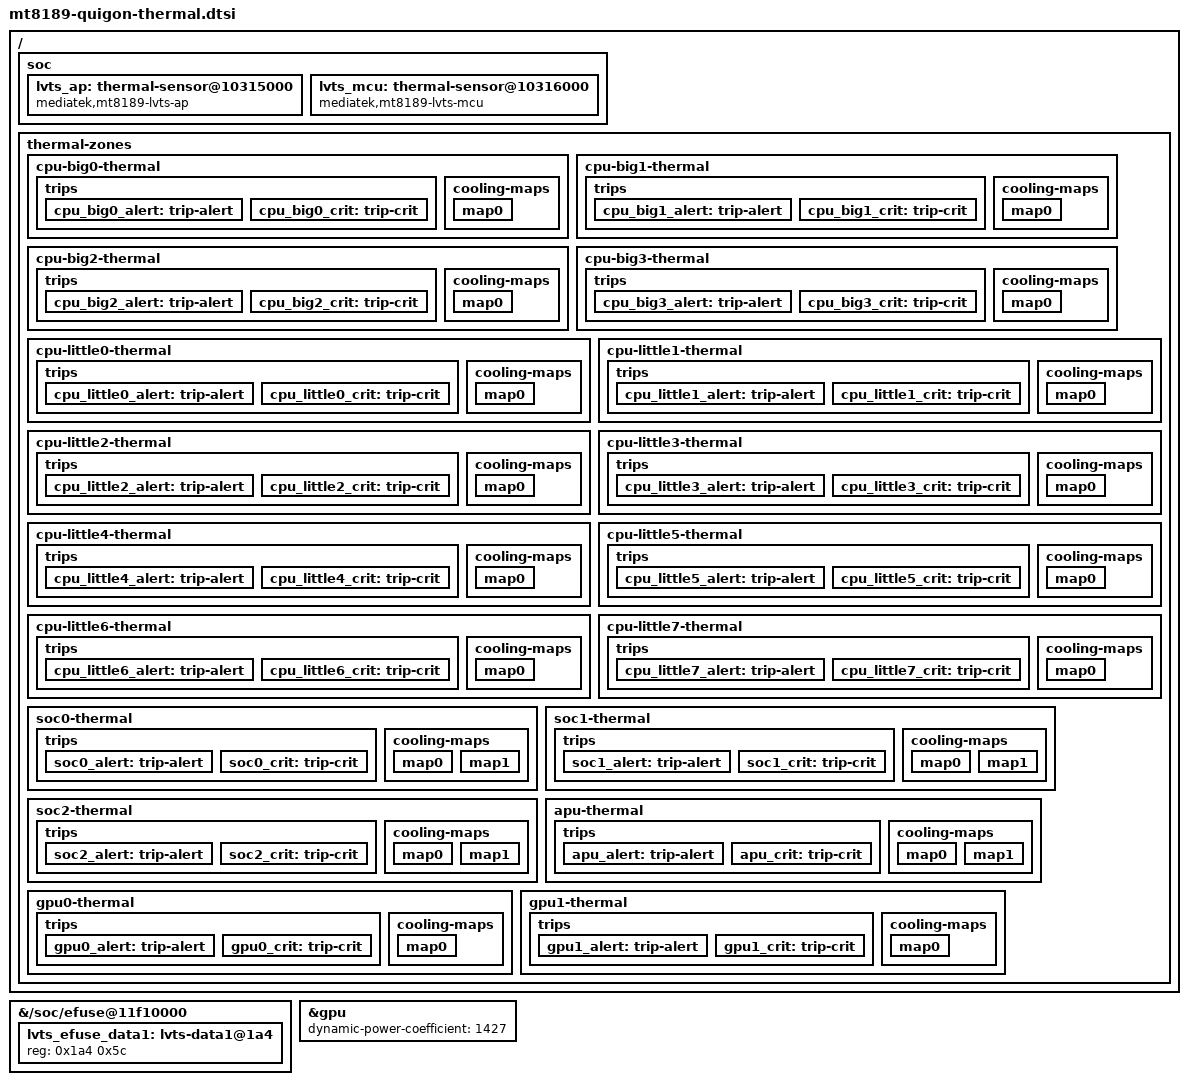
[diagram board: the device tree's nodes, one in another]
// SPDX-License-Identifier: (GPL-2.0 OR MIT)
/*
 * quigon thermal: the MT8189 LVTS sensors (two domains, 18 sensors) with thermal zones that throttle the CPU clusters
 * (mediatek-cpufreq-hw cooling devices) and the GPU (Panfrost devfreq cooling). Needs the MT8189 LVTS driver patch
 * (compatibles "mediatek,mt8189-lvts-mcu"/"-ap" and the MT8189_* sensor ids in mediatek,lvts-thermal.h).
 *
 * The firmware (coreboot) sets up every LVTS controller (device init, RC calibration, sampling, and the 119 C
 * hardware reset through the thermal protection stage 3) and marks it with 0x555 in LVTS_SPARE0; the driver keeps
 * that setup and only reads the golden temperature from the efuse. Like ChromeOS, no LVTS clock or reset is
 * described (the clock gate isn't modelled and resetting would drop the firmware calibration and protection); the
 * binding wants a clock, so the always-on 26 MHz reference stands in.
 *
 * Sensor layout from ChromeOS's mt8189.dtsi and coreboot: MCU controller 0 = big CPUs (2 sensors per A78),
 * MCU controllers 1-2 = little CPUs, AP controller 0 = SoC top x3 + APU, AP controller 1 (MFG) = GPU x2.
 * Efuse words 0-22 at 0x1a4: golden temperature in word 0 [7:0], per-sensor calibration in [23:0].
 *
 * Policy: ChromeOS throttles on one "max of all sensors" zone (power allocator, target 85 C, critical 115 C) and
 * gives every sensor a 119 C critical trip. Mainline LVTS has no max-of-all sensor, so every sensor gets a passive
 * trip at 85 C (step_wise) mapped to the cooling devices next to it, and a critical trip at 115 C.
 */
#include <dt-bindings/thermal/thermal.h>
#include <dt-bindings/thermal/mediatek,lvts-thermal.h>

&{/soc/efuse@11f10000} {
	lvts_efuse_data1: lvts-data1@1a4 {
		reg = <0x1a4 0x5c>;
	};
};

&gpu {
	/* ChromeOS value; lets the devfreq cooling device register an energy model */
	dynamic-power-coefficient = <1427>;
};

/ {
	soc {
		lvts_ap: thermal-sensor@10315000 {
			compatible = "mediatek,mt8189-lvts-ap";
			reg = <0 0x10315000 0 0x1000>;
			interrupts = <GIC_SPI 218 IRQ_TYPE_LEVEL_HIGH 0>;
			clocks = <&clk26m>;
			nvmem-cells = <&lvts_efuse_data1>;
			nvmem-cell-names = "lvts-calib-data-1";
			#thermal-sensor-cells = <1>;
		};

		lvts_mcu: thermal-sensor@10316000 {
			compatible = "mediatek,mt8189-lvts-mcu";
			reg = <0 0x10316000 0 0x1000>;
			interrupts = <GIC_SPI 219 IRQ_TYPE_LEVEL_HIGH 0>;
			clocks = <&clk26m>;
			nvmem-cells = <&lvts_efuse_data1>;
			nvmem-cell-names = "lvts-calib-data-1";
			#thermal-sensor-cells = <1>;
		};
	};

	thermal-zones {
		cpu-big0-thermal {
			polling-delay = <1000>;
			polling-delay-passive = <100>;
			thermal-sensors = <&lvts_mcu MT8189_MCU_BIG_CPU0>;

			trips {
				cpu_big0_alert: trip-alert {
					temperature = <85000>;
					hysteresis = <2000>;
					type = "passive";
				};

				cpu_big0_crit: trip-crit {
					temperature = <115000>;
					hysteresis = <0>;
					type = "critical";
				};
			};

			cooling-maps {
				map0 {
					trip = <&cpu_big0_alert>;
					cooling-device = <&cpu6 THERMAL_NO_LIMIT THERMAL_NO_LIMIT>,
							 <&cpu7 THERMAL_NO_LIMIT THERMAL_NO_LIMIT>;
				};
			};
		};

		cpu-big1-thermal {
			polling-delay = <1000>;
			polling-delay-passive = <100>;
			thermal-sensors = <&lvts_mcu MT8189_MCU_BIG_CPU1>;

			trips {
				cpu_big1_alert: trip-alert {
					temperature = <85000>;
					hysteresis = <2000>;
					type = "passive";
				};

				cpu_big1_crit: trip-crit {
					temperature = <115000>;
					hysteresis = <0>;
					type = "critical";
				};
			};

			cooling-maps {
				map0 {
					trip = <&cpu_big1_alert>;
					cooling-device = <&cpu6 THERMAL_NO_LIMIT THERMAL_NO_LIMIT>,
							 <&cpu7 THERMAL_NO_LIMIT THERMAL_NO_LIMIT>;
				};
			};
		};

		cpu-big2-thermal {
			polling-delay = <1000>;
			polling-delay-passive = <100>;
			thermal-sensors = <&lvts_mcu MT8189_MCU_BIG_CPU2>;

			trips {
				cpu_big2_alert: trip-alert {
					temperature = <85000>;
					hysteresis = <2000>;
					type = "passive";
				};

				cpu_big2_crit: trip-crit {
					temperature = <115000>;
					hysteresis = <0>;
					type = "critical";
				};
			};

			cooling-maps {
				map0 {
					trip = <&cpu_big2_alert>;
					cooling-device = <&cpu6 THERMAL_NO_LIMIT THERMAL_NO_LIMIT>,
							 <&cpu7 THERMAL_NO_LIMIT THERMAL_NO_LIMIT>;
				};
			};
		};

		cpu-big3-thermal {
			polling-delay = <1000>;
			polling-delay-passive = <100>;
			thermal-sensors = <&lvts_mcu MT8189_MCU_BIG_CPU3>;

			trips {
				cpu_big3_alert: trip-alert {
					temperature = <85000>;
					hysteresis = <2000>;
					type = "passive";
				};

				cpu_big3_crit: trip-crit {
					temperature = <115000>;
					hysteresis = <0>;
					type = "critical";
				};
			};

			cooling-maps {
				map0 {
					trip = <&cpu_big3_alert>;
					cooling-device = <&cpu6 THERMAL_NO_LIMIT THERMAL_NO_LIMIT>,
							 <&cpu7 THERMAL_NO_LIMIT THERMAL_NO_LIMIT>;
				};
			};
		};

		cpu-little0-thermal {
			polling-delay = <1000>;
			polling-delay-passive = <100>;
			thermal-sensors = <&lvts_mcu MT8189_MCU_LITTLE_CPU0>;

			trips {
				cpu_little0_alert: trip-alert {
					temperature = <85000>;
					hysteresis = <2000>;
					type = "passive";
				};

				cpu_little0_crit: trip-crit {
					temperature = <115000>;
					hysteresis = <0>;
					type = "critical";
				};
			};

			cooling-maps {
				map0 {
					trip = <&cpu_little0_alert>;
					cooling-device = <&cpu0 THERMAL_NO_LIMIT THERMAL_NO_LIMIT>,
							 <&cpu1 THERMAL_NO_LIMIT THERMAL_NO_LIMIT>,
							 <&cpu2 THERMAL_NO_LIMIT THERMAL_NO_LIMIT>,
							 <&cpu3 THERMAL_NO_LIMIT THERMAL_NO_LIMIT>,
							 <&cpu4 THERMAL_NO_LIMIT THERMAL_NO_LIMIT>,
							 <&cpu5 THERMAL_NO_LIMIT THERMAL_NO_LIMIT>;
				};
			};
		};

		cpu-little1-thermal {
			polling-delay = <1000>;
			polling-delay-passive = <100>;
			thermal-sensors = <&lvts_mcu MT8189_MCU_LITTLE_CPU1>;

			trips {
				cpu_little1_alert: trip-alert {
					temperature = <85000>;
					hysteresis = <2000>;
					type = "passive";
				};

				cpu_little1_crit: trip-crit {
					temperature = <115000>;
					hysteresis = <0>;
					type = "critical";
				};
			};

			cooling-maps {
				map0 {
					trip = <&cpu_little1_alert>;
					cooling-device = <&cpu0 THERMAL_NO_LIMIT THERMAL_NO_LIMIT>,
							 <&cpu1 THERMAL_NO_LIMIT THERMAL_NO_LIMIT>,
							 <&cpu2 THERMAL_NO_LIMIT THERMAL_NO_LIMIT>,
							 <&cpu3 THERMAL_NO_LIMIT THERMAL_NO_LIMIT>,
							 <&cpu4 THERMAL_NO_LIMIT THERMAL_NO_LIMIT>,
							 <&cpu5 THERMAL_NO_LIMIT THERMAL_NO_LIMIT>;
				};
			};
		};

		cpu-little2-thermal {
			polling-delay = <1000>;
			polling-delay-passive = <100>;
			thermal-sensors = <&lvts_mcu MT8189_MCU_LITTLE_CPU2>;

			trips {
				cpu_little2_alert: trip-alert {
					temperature = <85000>;
					hysteresis = <2000>;
					type = "passive";
				};

				cpu_little2_crit: trip-crit {
					temperature = <115000>;
					hysteresis = <0>;
					type = "critical";
				};
			};

			cooling-maps {
				map0 {
					trip = <&cpu_little2_alert>;
					cooling-device = <&cpu0 THERMAL_NO_LIMIT THERMAL_NO_LIMIT>,
							 <&cpu1 THERMAL_NO_LIMIT THERMAL_NO_LIMIT>,
							 <&cpu2 THERMAL_NO_LIMIT THERMAL_NO_LIMIT>,
							 <&cpu3 THERMAL_NO_LIMIT THERMAL_NO_LIMIT>,
							 <&cpu4 THERMAL_NO_LIMIT THERMAL_NO_LIMIT>,
							 <&cpu5 THERMAL_NO_LIMIT THERMAL_NO_LIMIT>;
				};
			};
		};

		cpu-little3-thermal {
			polling-delay = <1000>;
			polling-delay-passive = <100>;
			thermal-sensors = <&lvts_mcu MT8189_MCU_LITTLE_CPU3>;

			trips {
				cpu_little3_alert: trip-alert {
					temperature = <85000>;
					hysteresis = <2000>;
					type = "passive";
				};

				cpu_little3_crit: trip-crit {
					temperature = <115000>;
					hysteresis = <0>;
					type = "critical";
				};
			};

			cooling-maps {
				map0 {
					trip = <&cpu_little3_alert>;
					cooling-device = <&cpu0 THERMAL_NO_LIMIT THERMAL_NO_LIMIT>,
							 <&cpu1 THERMAL_NO_LIMIT THERMAL_NO_LIMIT>,
							 <&cpu2 THERMAL_NO_LIMIT THERMAL_NO_LIMIT>,
							 <&cpu3 THERMAL_NO_LIMIT THERMAL_NO_LIMIT>,
							 <&cpu4 THERMAL_NO_LIMIT THERMAL_NO_LIMIT>,
							 <&cpu5 THERMAL_NO_LIMIT THERMAL_NO_LIMIT>;
				};
			};
		};

		cpu-little4-thermal {
			polling-delay = <1000>;
			polling-delay-passive = <100>;
			thermal-sensors = <&lvts_mcu MT8189_MCU_LITTLE_CPU4>;

			trips {
				cpu_little4_alert: trip-alert {
					temperature = <85000>;
					hysteresis = <2000>;
					type = "passive";
				};

				cpu_little4_crit: trip-crit {
					temperature = <115000>;
					hysteresis = <0>;
					type = "critical";
				};
			};

			cooling-maps {
				map0 {
					trip = <&cpu_little4_alert>;
					cooling-device = <&cpu0 THERMAL_NO_LIMIT THERMAL_NO_LIMIT>,
							 <&cpu1 THERMAL_NO_LIMIT THERMAL_NO_LIMIT>,
							 <&cpu2 THERMAL_NO_LIMIT THERMAL_NO_LIMIT>,
							 <&cpu3 THERMAL_NO_LIMIT THERMAL_NO_LIMIT>,
							 <&cpu4 THERMAL_NO_LIMIT THERMAL_NO_LIMIT>,
							 <&cpu5 THERMAL_NO_LIMIT THERMAL_NO_LIMIT>;
				};
			};
		};

		cpu-little5-thermal {
			polling-delay = <1000>;
			polling-delay-passive = <100>;
			thermal-sensors = <&lvts_mcu MT8189_MCU_LITTLE_CPU5>;

			trips {
				cpu_little5_alert: trip-alert {
					temperature = <85000>;
					hysteresis = <2000>;
					type = "passive";
				};

				cpu_little5_crit: trip-crit {
					temperature = <115000>;
					hysteresis = <0>;
					type = "critical";
				};
			};

			cooling-maps {
				map0 {
					trip = <&cpu_little5_alert>;
					cooling-device = <&cpu0 THERMAL_NO_LIMIT THERMAL_NO_LIMIT>,
							 <&cpu1 THERMAL_NO_LIMIT THERMAL_NO_LIMIT>,
							 <&cpu2 THERMAL_NO_LIMIT THERMAL_NO_LIMIT>,
							 <&cpu3 THERMAL_NO_LIMIT THERMAL_NO_LIMIT>,
							 <&cpu4 THERMAL_NO_LIMIT THERMAL_NO_LIMIT>,
							 <&cpu5 THERMAL_NO_LIMIT THERMAL_NO_LIMIT>;
				};
			};
		};

		cpu-little6-thermal {
			polling-delay = <1000>;
			polling-delay-passive = <100>;
			thermal-sensors = <&lvts_mcu MT8189_MCU_LITTLE_CPU6>;

			trips {
				cpu_little6_alert: trip-alert {
					temperature = <85000>;
					hysteresis = <2000>;
					type = "passive";
				};

				cpu_little6_crit: trip-crit {
					temperature = <115000>;
					hysteresis = <0>;
					type = "critical";
				};
			};

			cooling-maps {
				map0 {
					trip = <&cpu_little6_alert>;
					cooling-device = <&cpu0 THERMAL_NO_LIMIT THERMAL_NO_LIMIT>,
							 <&cpu1 THERMAL_NO_LIMIT THERMAL_NO_LIMIT>,
							 <&cpu2 THERMAL_NO_LIMIT THERMAL_NO_LIMIT>,
							 <&cpu3 THERMAL_NO_LIMIT THERMAL_NO_LIMIT>,
							 <&cpu4 THERMAL_NO_LIMIT THERMAL_NO_LIMIT>,
							 <&cpu5 THERMAL_NO_LIMIT THERMAL_NO_LIMIT>;
				};
			};
		};

		cpu-little7-thermal {
			polling-delay = <1000>;
			polling-delay-passive = <100>;
			thermal-sensors = <&lvts_mcu MT8189_MCU_LITTLE_CPU7>;

			trips {
				cpu_little7_alert: trip-alert {
					temperature = <85000>;
					hysteresis = <2000>;
					type = "passive";
				};

				cpu_little7_crit: trip-crit {
					temperature = <115000>;
					hysteresis = <0>;
					type = "critical";
				};
			};

			cooling-maps {
				map0 {
					trip = <&cpu_little7_alert>;
					cooling-device = <&cpu0 THERMAL_NO_LIMIT THERMAL_NO_LIMIT>,
							 <&cpu1 THERMAL_NO_LIMIT THERMAL_NO_LIMIT>,
							 <&cpu2 THERMAL_NO_LIMIT THERMAL_NO_LIMIT>,
							 <&cpu3 THERMAL_NO_LIMIT THERMAL_NO_LIMIT>,
							 <&cpu4 THERMAL_NO_LIMIT THERMAL_NO_LIMIT>,
							 <&cpu5 THERMAL_NO_LIMIT THERMAL_NO_LIMIT>;
				};
			};
		};

		soc0-thermal {
			polling-delay = <1000>;
			polling-delay-passive = <250>;
			thermal-sensors = <&lvts_ap MT8189_AP_SOC0>;

			trips {
				soc0_alert: trip-alert {
					temperature = <85000>;
					hysteresis = <2000>;
					type = "passive";
				};

				soc0_crit: trip-crit {
					temperature = <115000>;
					hysteresis = <0>;
					type = "critical";
				};
			};

			cooling-maps {
				map0 {
					trip = <&soc0_alert>;
					cooling-device = <&cpu0 THERMAL_NO_LIMIT THERMAL_NO_LIMIT>,
							 <&cpu1 THERMAL_NO_LIMIT THERMAL_NO_LIMIT>,
							 <&cpu2 THERMAL_NO_LIMIT THERMAL_NO_LIMIT>,
							 <&cpu3 THERMAL_NO_LIMIT THERMAL_NO_LIMIT>,
							 <&cpu4 THERMAL_NO_LIMIT THERMAL_NO_LIMIT>,
							 <&cpu5 THERMAL_NO_LIMIT THERMAL_NO_LIMIT>,
							 <&cpu6 THERMAL_NO_LIMIT THERMAL_NO_LIMIT>,
							 <&cpu7 THERMAL_NO_LIMIT THERMAL_NO_LIMIT>;
				};

				map1 {
					trip = <&soc0_alert>;
					cooling-device = <&gpu THERMAL_NO_LIMIT THERMAL_NO_LIMIT>;
				};
			};
		};

		soc1-thermal {
			polling-delay = <1000>;
			polling-delay-passive = <250>;
			thermal-sensors = <&lvts_ap MT8189_AP_SOC1>;

			trips {
				soc1_alert: trip-alert {
					temperature = <85000>;
					hysteresis = <2000>;
					type = "passive";
				};

				soc1_crit: trip-crit {
					temperature = <115000>;
					hysteresis = <0>;
					type = "critical";
				};
			};

			cooling-maps {
				map0 {
					trip = <&soc1_alert>;
					cooling-device = <&cpu0 THERMAL_NO_LIMIT THERMAL_NO_LIMIT>,
							 <&cpu1 THERMAL_NO_LIMIT THERMAL_NO_LIMIT>,
							 <&cpu2 THERMAL_NO_LIMIT THERMAL_NO_LIMIT>,
							 <&cpu3 THERMAL_NO_LIMIT THERMAL_NO_LIMIT>,
							 <&cpu4 THERMAL_NO_LIMIT THERMAL_NO_LIMIT>,
							 <&cpu5 THERMAL_NO_LIMIT THERMAL_NO_LIMIT>,
							 <&cpu6 THERMAL_NO_LIMIT THERMAL_NO_LIMIT>,
							 <&cpu7 THERMAL_NO_LIMIT THERMAL_NO_LIMIT>;
				};

				map1 {
					trip = <&soc1_alert>;
					cooling-device = <&gpu THERMAL_NO_LIMIT THERMAL_NO_LIMIT>;
				};
			};
		};

		soc2-thermal {
			polling-delay = <1000>;
			polling-delay-passive = <250>;
			thermal-sensors = <&lvts_ap MT8189_AP_SOC2>;

			trips {
				soc2_alert: trip-alert {
					temperature = <85000>;
					hysteresis = <2000>;
					type = "passive";
				};

				soc2_crit: trip-crit {
					temperature = <115000>;
					hysteresis = <0>;
					type = "critical";
				};
			};

			cooling-maps {
				map0 {
					trip = <&soc2_alert>;
					cooling-device = <&cpu0 THERMAL_NO_LIMIT THERMAL_NO_LIMIT>,
							 <&cpu1 THERMAL_NO_LIMIT THERMAL_NO_LIMIT>,
							 <&cpu2 THERMAL_NO_LIMIT THERMAL_NO_LIMIT>,
							 <&cpu3 THERMAL_NO_LIMIT THERMAL_NO_LIMIT>,
							 <&cpu4 THERMAL_NO_LIMIT THERMAL_NO_LIMIT>,
							 <&cpu5 THERMAL_NO_LIMIT THERMAL_NO_LIMIT>,
							 <&cpu6 THERMAL_NO_LIMIT THERMAL_NO_LIMIT>,
							 <&cpu7 THERMAL_NO_LIMIT THERMAL_NO_LIMIT>;
				};

				map1 {
					trip = <&soc2_alert>;
					cooling-device = <&gpu THERMAL_NO_LIMIT THERMAL_NO_LIMIT>;
				};
			};
		};

		apu-thermal {
			polling-delay = <1000>;
			polling-delay-passive = <250>;
			thermal-sensors = <&lvts_ap MT8189_AP_APU>;

			trips {
				apu_alert: trip-alert {
					temperature = <85000>;
					hysteresis = <2000>;
					type = "passive";
				};

				apu_crit: trip-crit {
					temperature = <115000>;
					hysteresis = <0>;
					type = "critical";
				};
			};

			cooling-maps {
				map0 {
					trip = <&apu_alert>;
					cooling-device = <&cpu0 THERMAL_NO_LIMIT THERMAL_NO_LIMIT>,
							 <&cpu1 THERMAL_NO_LIMIT THERMAL_NO_LIMIT>,
							 <&cpu2 THERMAL_NO_LIMIT THERMAL_NO_LIMIT>,
							 <&cpu3 THERMAL_NO_LIMIT THERMAL_NO_LIMIT>,
							 <&cpu4 THERMAL_NO_LIMIT THERMAL_NO_LIMIT>,
							 <&cpu5 THERMAL_NO_LIMIT THERMAL_NO_LIMIT>,
							 <&cpu6 THERMAL_NO_LIMIT THERMAL_NO_LIMIT>,
							 <&cpu7 THERMAL_NO_LIMIT THERMAL_NO_LIMIT>;
				};

				map1 {
					trip = <&apu_alert>;
					cooling-device = <&gpu THERMAL_NO_LIMIT THERMAL_NO_LIMIT>;
				};
			};
		};

		gpu0-thermal {
			polling-delay = <1000>;
			polling-delay-passive = <100>;
			thermal-sensors = <&lvts_ap MT8189_AP_GPU0>;

			trips {
				gpu0_alert: trip-alert {
					temperature = <85000>;
					hysteresis = <2000>;
					type = "passive";
				};

				gpu0_crit: trip-crit {
					temperature = <115000>;
					hysteresis = <0>;
					type = "critical";
				};
			};

			cooling-maps {
				map0 {
					trip = <&gpu0_alert>;
					cooling-device = <&gpu THERMAL_NO_LIMIT THERMAL_NO_LIMIT>;
				};
			};
		};

		gpu1-thermal {
			polling-delay = <1000>;
			polling-delay-passive = <100>;
			thermal-sensors = <&lvts_ap MT8189_AP_GPU1>;

			trips {
				gpu1_alert: trip-alert {
					temperature = <85000>;
					hysteresis = <2000>;
					type = "passive";
				};

				gpu1_crit: trip-crit {
					temperature = <115000>;
					hysteresis = <0>;
					type = "critical";
				};
			};

			cooling-maps {
				map0 {
					trip = <&gpu1_alert>;
					cooling-device = <&gpu THERMAL_NO_LIMIT THERMAL_NO_LIMIT>;
				};
			};
		};
	};
};
